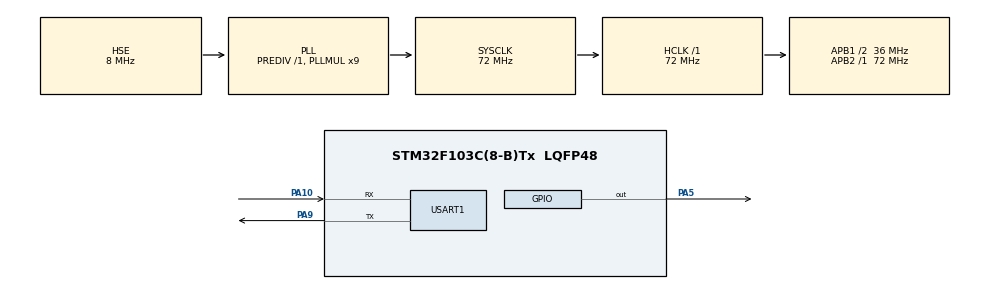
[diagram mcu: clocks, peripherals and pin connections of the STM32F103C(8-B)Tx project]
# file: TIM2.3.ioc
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Mcu.Family=STM32F1
Mcu.Name=STM32F103C(8-B)Tx
Mcu.Package=LQFP48
NVIC.PriorityGroup=NVIC_PRIORITYGROUP_4
NVIC.TIM2_IRQn=true\:1\:0\:true\:false\:true\:true\:true\:true
NVIC.TIM3_IRQn=true\:0\:0\:false\:false\:true\:true\:true\:true
PA10.Mode=Asynchronous
PA10.Signal=USART1_RX
PA13.Mode=Serial_Wire
PA13.Signal=SYS_JTMS-SWDIO
PA14.Mode=Serial_Wire
PA14.Signal=SYS_JTCK-SWCLK
PA5.Signal=GPIO_Output
PA9.Mode=Asynchronous
PA9.Signal=USART1_TX
PD0-OSC_IN.Mode=HSE-External-Oscillator
PD0-OSC_IN.Signal=RCC_OSC_IN
PD1-OSC_OUT.Mode=HSE-External-Oscillator
PD1-OSC_OUT.Signal=RCC_OSC_OUT
ProjectManager.HeapSize=0x200
ProjectManager.StackSize=0x400
ProjectManager.TargetToolchain=MDK-ARM V5
RCC.AHBFreq_Value=72000000
RCC.APB1CLKDivider=RCC_HCLK_DIV2
RCC.APB1Freq_Value=36000000
RCC.APB1TimFreq_Value=72000000
RCC.APB2Freq_Value=72000000
RCC.APB2TimFreq_Value=72000000
RCC.HCLKFreq_Value=72000000
RCC.PLLMUL=RCC_PLL_MUL9
RCC.PLLSourceVirtual=RCC_PLLSOURCE_HSE
RCC.SYSCLKFreq_VALUE=72000000
RCC.SYSCLKSource=RCC_SYSCLKSOURCE_PLLCLK
RCC.USBFreq_Value=72000000
TIM2.AutoReloadPreload=TIM_AUTORELOAD_PRELOAD_ENABLE
TIM2.Period=19999
TIM2.Prescaler=7199
TIM3.AutoReloadPreload=TIM_AUTORELOAD_PRELOAD_ENABLE
TIM3.Period=49999
TIM3.Prescaler=7199
USART1.VirtualMode=VM_ASYNC
VP_TIM2_VS_ClockSourceINT.Mode=Internal
VP_TIM3_VS_ClockSourceINT.Mode=Internal
board=custom

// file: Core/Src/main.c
/* USER CODE BEGIN Header */
/**
  ******************************************************************************
  * @file           : main.c
  * @brief          : Main program body
  ******************************************************************************
  * @attention
  *
  * Copyright (c) 2025 STMicroelectronics.
  * All rights reserved.
  *
  * This software is licensed under terms that can be found in the LICENSE file
  * in the root directory of this software component.
  * If no LICENSE file comes with this software, it is provided AS-IS.
  *
  ******************************************************************************
  */
/* USER CODE END Header */
#include "main.h"
#include "tim.h"
#include "usart.h"
#include "gpio.h"

/* USER CODE BEGIN PV */
uint8_t uart_send_flag = 0;  // 串口发送标志（5秒触发一次）
uint8_t led_toggle_flag = 0; // LED闪烁标志（2秒触发一次）
/* USER CODE END PV */

void SystemClock_Config(void);

/* USER CODE BEGIN 0 */
// 定时器中断回调函数：当定时器计数到ARR时触发
void HAL_TIM_PeriodElapsedCallback(TIM_HandleTypeDef *htim)
{
  if (htim->Instance == TIM2)  // TIM2触发（2秒）
  {
    led_toggle_flag = 1;  // 置位LED闪烁标志
  }
  else if (htim->Instance == TIM3)  // TIM3触发（5秒）
  {
    uart_send_flag = 1;   // 置位串口发送标志
  }
}
/* USER CODE END 0 */
int main(void)
{

  /* MCU Configuration--------------------------------------------------------*/

  /* Reset of all peripherals, Initializes the Flash interface and the Systick. */
  HAL_Init();

  /* Configure the system clock */
  SystemClock_Config();

  /* Initialize all configured peripherals */
  MX_GPIO_Init();
  MX_TIM2_Init();
  MX_TIM3_Init();
  MX_USART1_UART_Init();
  /* USER CODE BEGIN 2 */
// 启动TIM2和TIM3的定时中断
HAL_TIM_Base_Start_IT(&htim2);  // 启动2秒定时器
HAL_TIM_Base_Start_IT(&htim3);  // 启动5秒定时器
/* USER CODE END 2 */

/* Infinite loop */
while (1)
{

  /* USER CODE BEGIN 3 */
  // 处理LED闪烁（检测到标志位则翻转LED）
  if (led_toggle_flag)
  {
    HAL_GPIO_TogglePin(GPIOA, GPIO_PIN_5);  // 翻转PA5电平（LED亮/灭切换）
    led_toggle_flag = 0;  // 清除标志位
  }

  // 处理串口发送（检测到标志位则发送数据）
  if (uart_send_flag)
  {
    uint8_t send_data[] = "hello windows!\r\n";  // 要发送的字符串
    // 发送数据：参数分别为串口句柄、数据地址、长度、超时时间
    HAL_UART_Transmit(&huart1, send_data, sizeof(send_data)-1, 100);
    uart_send_flag = 0;  // 清除标志位
  }
}
/* USER CODE END 3 */
}
void SystemClock_Config(void)
{
  RCC_OscInitTypeDef RCC_OscInitStruct = {0};
  RCC_ClkInitTypeDef RCC_ClkInitStruct = {0};

  /** Initializes the RCC Oscillators according to the specified parameters
  * in the RCC_OscInitTypeDef structure.
  */
  RCC_OscInitStruct.OscillatorType = RCC_OSCILLATORTYPE_HSE;
  RCC_OscInitStruct.HSEState = RCC_HSE_ON;
  RCC_OscInitStruct.HSEPredivValue = RCC_HSE_PREDIV_DIV1;
  RCC_OscInitStruct.HSIState = RCC_HSI_ON;
  RCC_OscInitStruct.PLL.PLLState = RCC_PLL_ON;
  RCC_OscInitStruct.PLL.PLLSource = RCC_PLLSOURCE_HSE;
  RCC_OscInitStruct.PLL.PLLMUL = RCC_PLL_MUL9;
  if (HAL_RCC_OscConfig(&RCC_OscInitStruct) != HAL_OK)
  {
    Error_Handler();
  }

  /** Initializes the CPU, AHB and APB buses clocks
  */
  RCC_ClkInitStruct.ClockType = RCC_CLOCKTYPE_HCLK|RCC_CLOCKTYPE_SYSCLK
                              |RCC_CLOCKTYPE_PCLK1|RCC_CLOCKTYPE_PCLK2;
  RCC_ClkInitStruct.SYSCLKSource = RCC_SYSCLKSOURCE_PLLCLK;
  RCC_ClkInitStruct.AHBCLKDivider = RCC_SYSCLK_DIV1;
  RCC_ClkInitStruct.APB1CLKDivider = RCC_HCLK_DIV2;
  RCC_ClkInitStruct.APB2CLKDivider = RCC_HCLK_DIV1;

  if (HAL_RCC_ClockConfig(&RCC_ClkInitStruct, FLASH_LATENCY_2) != HAL_OK)
  {
    Error_Handler();
  }
}

void Error_Handler(void)
{
  __disable_irq();
  while (1)
  {
  }
}
